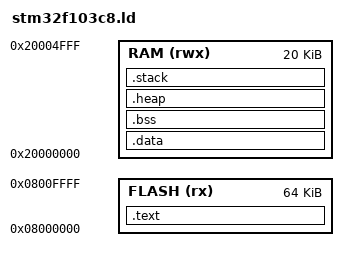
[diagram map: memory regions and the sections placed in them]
/* STM32F103C8 linker script for arm-none-eabi-gcc */
MEMORY
{
    FLASH (rx) : ORIGIN = 0x08000000, LENGTH = 64K
    RAM (rwx)  : ORIGIN = 0x20000000, LENGTH = 20K
}

ENTRY(Reset_Handler)

SECTIONS
{
    .text :
    {
        KEEP(*(.isr_vector))
        *(.text*)
        *(.rodata*)
        . = ALIGN(4);
        _etext = .;
    } > FLASH

    .data : AT (ADDR(.text) + SIZEOF(.text))
    {
        _sdata = .;
        *(.data*)
        . = ALIGN(4);
        _edata = .;
    } > RAM

    .bss :
    {
        _sbss = .;
        *(.bss*)
        *(COMMON)
        . = ALIGN(4);
        _ebss = .;
    } > RAM

    .heap : ALIGN(8)
    {
        _sheap = .;
        . = . + 2K;
        _eheap = .;
    } > RAM

    .stack : ALIGN(8)
    {
        _sstack = .;
        . = . + 1K;
        _estack = .;
    } > RAM
}
